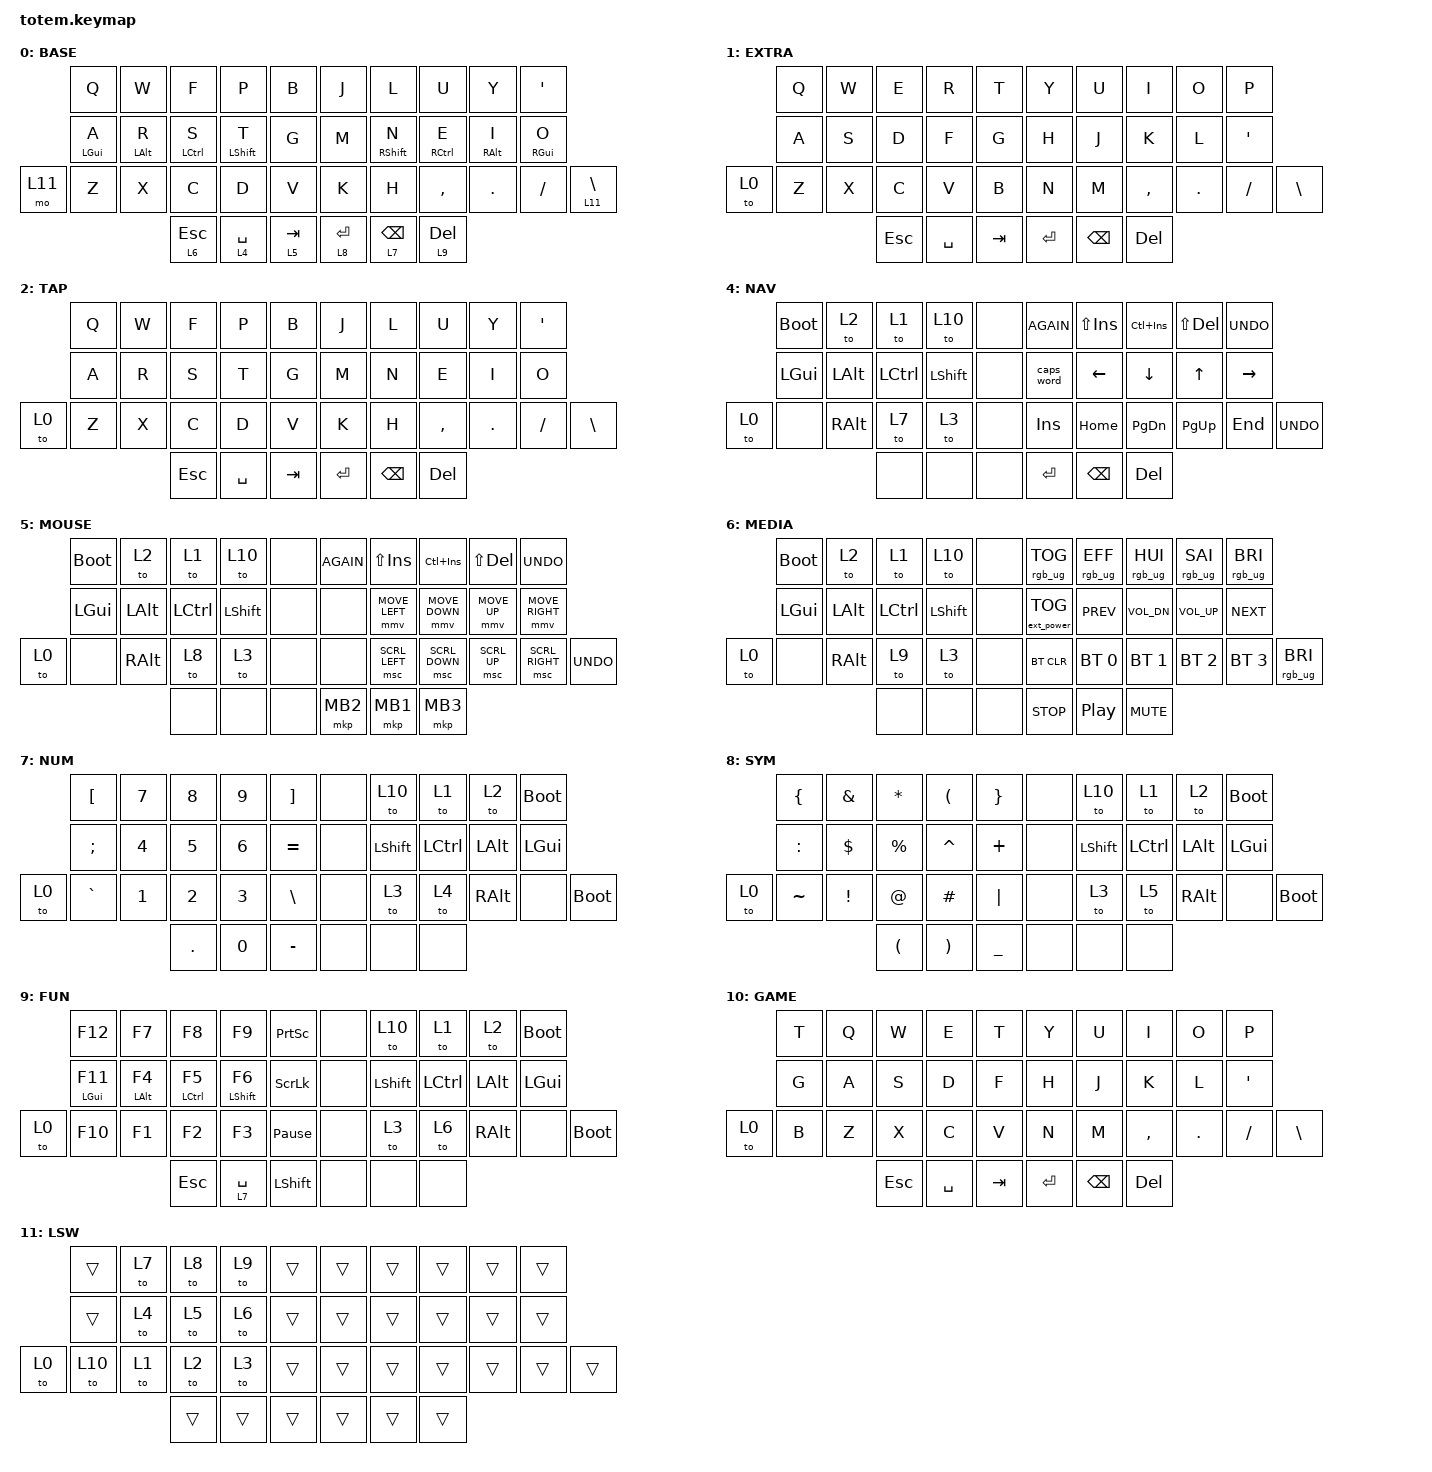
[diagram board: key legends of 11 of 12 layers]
/*
 * Miryoku layout for Totem (38-key, xiao_ble)
 * Base: Colemak-DH with home-row mods
 * All 10 Miryoku layers: BASE, EXTRA, TAP, BUTTON, NAV, MOUSE, MEDIA, NUM, SYM, FUN
 *
 * Mapping (from miryoku_zmk totem.h):
 *   pos0-9   = K00-K09 (top row)
 *   pos10-19 = K10-K19 (home row)
 *   pos20    = K00     (same as pos0, bottom left pinky column)
 *   pos21-30 = K20-K29 (bottom row)
 *   pos31    = K09     (same as pos9, bottom right pinky column)
 *   pos32-37 = K32-K37 (thumbs)
 */

#include <behaviors.dtsi>
#include <dt-bindings/zmk/bt.h>
#include <dt-bindings/zmk/ext_power.h>
#include <dt-bindings/zmk/keys.h>
#include <dt-bindings/zmk/pointing.h>
#include <dt-bindings/zmk/rgb.h>

#define BASE  0
#define EXTRA 1
#define TAP   2
#define BUTTON 3
#define NAV   4
#define MOUSE 5
#define MEDIA 6
#define NUM   7
#define SYM   8
#define FUN   9

&mt {
    flavor = "tap-preferred";
    tapping-term-ms = <160>;
    quick-tap-ms = <160>;
};

&lt {
    flavor = "tap-preferred";
    tapping-term-ms = <160>;
    quick-tap-ms = <160>;
};

/ {
    chosen { zmk,default-layer = &base_layer; };

    combos {
        compatible = "zmk,combos";

        combo_esc {
            timeout-ms = <50>;
            key-positions = <0 1>;
            bindings = <&kp ESC>;
        };
    };

    keymap {
        compatible = "zmk,keymap";

        base_layer: base_layer {
            label = "BASE";
            bindings = <
        &kp Q       &kp W       &kp F        &kp P        &kp B        &kp J        &kp L            &kp U         &kp Y       &kp SQT
        &mt LGUI A  &mt LALT R  &mt LCTRL S  &mt LSHFT T  &kp G        &kp M        &mt RSHFT N      &mt RCTRL E   &mt RALT I  &mt RGUI O
&mo 11  &kp Z       &kp X       &kp C        &kp D        &kp V        &kp K        &kp H            &kp COMMA     &kp DOT     &kp FSLH    &lt 11 BACKSLASH
                                &lt 6 ESC    &lt 4 SPACE  &lt 5 TAB    &lt 8 ENTER  &lt 7 BACKSPACE  &lt 9 DELETE
            >;
        };

        extra_layer {
            label = "EXTRA";
            bindings = <
       &kp Q  &kp W  &kp E    &kp R      &kp T      &kp Y    &kp U     &kp I      &kp O    &kp P
       &kp A  &kp S  &kp D    &kp F      &kp G      &kp H    &kp J     &kp K      &kp L    &kp SQT
&to 0  &kp Z  &kp X  &kp C    &kp V      &kp B      &kp N    &kp M     &kp COMMA  &kp DOT  &kp SLASH  &kp BSLH
                     &kp ESC  &kp SPACE  &kp TAB    &kp RET  &kp BSPC  &kp DEL
            >;
        };

        tap_layer {
            label = "TAP";
            bindings = <
       &kp Q  &kp W  &kp F    &kp P      &kp B      &kp J    &kp L     &kp U      &kp Y    &kp SQT
       &kp A  &kp R  &kp S    &kp T      &kp G      &kp M    &kp N     &kp E      &kp I    &kp O
&to 0  &kp Z  &kp X  &kp C    &kp D      &kp V      &kp K    &kp H     &kp COMMA  &kp DOT  &kp SLASH  &kp BSLH
                     &kp ESC  &kp SPACE  &kp TAB    &kp RET  &kp BSPC  &kp DEL
            >;
        };

        button_layer {
            label = "BUTTON";
            bindings = <
       &kp K_UNDO   &kp LS(DEL)  &kp LS(INS)  &kp LC(INS)  &kp K_AGAIN    &kp K_AGAIN  &kp LC(INS)  &kp LS(INS)  &kp LS(DEL)  &kp K_UNDO
       &kp LGUI     &kp LALT     &kp LCTRL    &kp LSHFT    &none          &none        &kp LSHFT    &kp LCTRL    &kp LALT     &kp LGUI
&to 0  &kp LS(DEL)  &kp LS(INS)  &kp LC(INS)  &kp K_AGAIN  &kp K_AGAIN    &kp LC(INS)  &kp LS(INS)  &kp LS(DEL)  &kp K_UNDO   &mkp MB3    &mkp MB1
                                 &mkp MB2     &mkp MB2     &mkp MB1       &mkp MB3
            >;
        };

        nav_layer {
            label = "NAV";
            bindings = <
       &bootloader  &to 2     &to 1      &to 10     &none    &kp K_AGAIN  &kp LS(INS)  &kp LC(INS)  &kp LS(DEL)  &kp K_UNDO
       &kp LGUI     &kp LALT  &kp LCTRL  &kp LSHFT  &none    &caps_word   &kp LEFT     &kp DOWN     &kp UP       &kp RIGHT
&to 0  &none        &kp RALT  &to 7      &to 3      &none    &kp INS      &kp HOME     &kp PG_DN    &kp PG_UP    &kp END     &kp K_UNDO
                              &none      &none      &none    &kp RET      &kp BSPC     &kp DEL
            >;
        };

        mouse_layer {
            label = "MOUSE";
            bindings = <
       &bootloader  &to 2     &to 1      &to 10     &none    &kp K_AGAIN  &kp LS(INS)     &kp LC(INS)     &kp LS(DEL)   &kp K_UNDO
       &kp LGUI     &kp LALT  &kp LCTRL  &kp LSHFT  &none    &none        &mmv MOVE_LEFT  &mmv MOVE_DOWN  &mmv MOVE_UP  &mmv MOVE_RIGHT
&to 0  &none        &kp RALT  &to 8      &to 3      &none    &none        &msc SCRL_LEFT  &msc SCRL_DOWN  &msc SCRL_UP  &msc SCRL_RIGHT  &kp K_UNDO
                              &none      &none      &none    &mkp MB2     &mkp MB1        &mkp MB3
            >;
        };

        media_layer {
            label = "MEDIA";
            bindings = <
       &bootloader  &to 2     &to 1      &to 10     &none    &rgb_ug RGB_TOG    &rgb_ug RGB_EFF  &rgb_ug RGB_HUI  &rgb_ug RGB_SAI  &rgb_ug RGB_BRI
       &kp LGUI     &kp LALT  &kp LCTRL  &kp LSHFT  &none    &ext_power EP_TOG  &kp C_PREV       &kp C_VOL_DN     &kp C_VOL_UP     &kp C_NEXT
&to 0  &none        &kp RALT  &to 9      &to 3      &none    &bt BT_CLR         &bt BT_SEL 0     &bt BT_SEL 1     &bt BT_SEL 2     &bt BT_SEL 3     &rgb_ug RGB_BRI
                              &none      &none      &none    &kp C_STOP         &kp C_PP         &kp C_MUTE
            >;
        };

        num_layer {
            label = "NUM";
            bindings = <
       &kp LBKT   &kp N7  &kp N8   &kp N9  &kp RBKT     &none  &to 10     &to 1      &to 2     &bootloader
       &kp SEMI   &kp N4  &kp N5   &kp N6  &kp EQUAL    &none  &kp LSHFT  &kp LCTRL  &kp LALT  &kp LGUI
&to 0  &kp GRAVE  &kp N1  &kp N2   &kp N3  &kp BSLH     &none  &to 3      &to 4      &kp RALT  &none        &bootloader
                          &kp DOT  &kp N0  &kp MINUS    &none  &none      &none
            >;
        };

        symbol_layer {
            label = "SYM";
            bindings = <
       &kp LBRC   &kp AMPS  &kp ASTRK  &kp LPAR   &kp RBRC     &none  &to 10     &to 1      &to 2     &bootloader
       &kp COLON  &kp DLLR  &kp PRCNT  &kp CARET  &kp PLUS     &none  &kp LSHFT  &kp LCTRL  &kp LALT  &kp LGUI
&to 0  &kp TILDE  &kp EXCL  &kp AT     &kp HASH   &kp PIPE     &none  &to 3      &to 5      &kp RALT  &none        &bootloader
                            &kp LPAR   &kp RPAR   &kp UNDER    &none  &none      &none
            >;
        };

        fn_layer {
            label = "FUN";
            bindings = <
       &kp F12           &kp F7           &kp F8               &kp F9             &kp PSCRN          &none  &to 10     &to 1      &to 2     &bootloader
       &mt LEFT_GUI F11  &mt LEFT_ALT F4  &mt LEFT_CONTROL F5  &mt LEFT_SHIFT F6  &kp SLCK           &none  &kp LSHFT  &kp LCTRL  &kp LALT  &kp LGUI
&to 0  &kp F10           &kp F1           &kp F2               &kp F3             &kp PAUSE_BREAK    &none  &to 3      &to 6      &kp RALT  &none        &bootloader
                                          &kp ESCAPE           &lt 7 SPACE        &kp LEFT_SHIFT     &none  &none      &none
            >;
        };

        game_layer {
            label = "GAME";
            bindings = <
       &kp T  &kp Q  &kp W    &kp E      &kp T      &kp Y    &kp U     &kp I      &kp O    &kp P
       &kp G  &kp A  &kp S    &kp D      &kp F      &kp H    &kp J     &kp K      &kp L    &kp SQT
&to 0  &kp B  &kp Z  &kp X    &kp C      &kp V      &kp N    &kp M     &kp COMMA  &kp DOT  &kp SLASH  &kp BSLH
                     &kp ESC  &kp SPACE  &kp TAB    &kp RET  &kp BSPC  &kp DEL
            >;
        };

        lsw_layer {
            bindings = <
       &trans  &to 7  &to 8   &to 9   &trans    &trans  &trans  &trans  &trans  &trans
       &trans  &to 4  &to 5   &to 6   &trans    &trans  &trans  &trans  &trans  &trans
&to 0  &to 10  &to 1  &to 2   &to 3   &trans    &trans  &trans  &trans  &trans  &trans  &trans
                      &trans  &trans  &trans    &trans  &trans  &trans
            >;

            label = "LSW";
        };
    };
};
